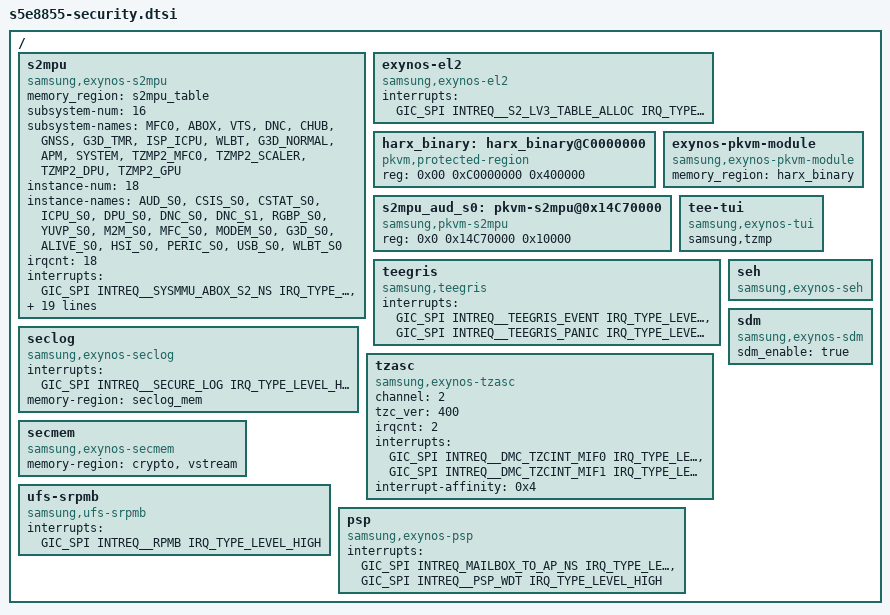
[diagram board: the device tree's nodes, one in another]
/*
 * SAMSUNG S5E8855 SoC security device tree source
 *
 * Copyright (c) 2024 Samsung Electronics Co., Ltd.
 *              http://www.samsung.com
 *
 * SAMSUNG S5E8855 SoC security device nodes are listed in this file.
 * EXYNOS based board files can include this file and provide
 * values for board specfic bindings.
 *
 * This program is free software; you can redistribute it and/or modify
 * it under the terms of the GNU General Public License version 2 as
 * published by the Free Software Foundation.
 */
#include <dt-bindings/interrupt-controller/s5e8855.h>
/ {
	s2mpu {
		compatible = "samsung,exynos-s2mpu";
		memory_region = <&s2mpu_table>;
		subsystem-num = <16>;
		subsystem-names = "MFC0",
				  "ABOX",
				  "VTS",
				  "DNC",
				  "CHUB",
				  "GNSS",
				  "G3D_TMR",
				  "ISP_ICPU",
				  "WLBT",
				  "G3D_NORMAL",
				  "APM",
				  "SYSTEM",
				  "TZMP2_MFC0",
				  "TZMP2_SCALER",
				  "TZMP2_DPU",
				  "TZMP2_GPU";
		instance-num = <18>;
		instance-names = "AUD_S0",
				 "CSIS_S0",
				 "CSTAT_S0",
				 "ICPU_S0",
				 "DPU_S0",
				 "DNC_S0",
				 "DNC_S1",
				 "RGBP_S0",
				 "YUVP_S0",
				 "M2M_S0",
				 "MFC_S0",
				 "MODEM_S0",
				 "G3D_S0",
				 "ALIVE_S0",
				 "HSI_S0",
				 "PERIC_S0",
				 "USB_S0",
				 "WLBT_S0";
		irqcnt = <18>;
		interrupts = <GIC_SPI INTREQ__SYSMMU_ABOX_S2_NS IRQ_TYPE_LEVEL_HIGH>,
			     <GIC_SPI INTREQ__SYSMMU_S0_CSIS_S2_NS IRQ_TYPE_LEVEL_HIGH>,
			     <GIC_SPI INTREQ__SYSMMU_S0_CSTAT_S2_NS IRQ_TYPE_LEVEL_HIGH>,
			     <GIC_SPI INTREQ__SYSMMU_S0_ICPU_S2_NS IRQ_TYPE_LEVEL_HIGH>,
			     <GIC_SPI INTREQ__SYSMMU_DPU_S0_STAGE2_NONSEC IRQ_TYPE_LEVEL_HIGH>,
			     <GIC_SPI INTREQ__FROM_DNC_SYSMMU_DNC_S0_O_STAGE2_NONSEC IRQ_TYPE_LEVEL_HIGH>,
			     <GIC_SPI INTREQ__FROM_DNC_SYSMMU_DNC_S1_O_STAGE2_NONSEC IRQ_TYPE_LEVEL_HIGH>,
			     <GIC_SPI INTREQ__SYSMMU_S0_RGBP_S2_NS IRQ_TYPE_LEVEL_HIGH>,
			     <GIC_SPI INTREQ__SYSMMU_S0_YUVP_S2_NS IRQ_TYPE_LEVEL_HIGH>,
			     <GIC_SPI INTREQ__SYSMMU_S0_M2M_STAGE2_NONSEC IRQ_TYPE_LEVEL_HIGH>,
			     <GIC_SPI INTREQ__SYSMMU_MFC_S0_interrupt_s2_ns IRQ_TYPE_LEVEL_HIGH>,
			     <GIC_SPI INTREQ_SYSMMU_MODEM_S2_NS IRQ_TYPE_LEVEL_HIGH>,
			     <GIC_SPI INTREQ_S2MPU_G3D_S2_NS IRQ_TYPE_LEVEL_HIGH>,
			     <GIC_SPI O_INTERRUPT_STAGE2_NONSEC_ALIVE IRQ_TYPE_LEVEL_HIGH>,
			     <GIC_SPI INTREQ__S2MPU_HSI_S0_S2_NS IRQ_TYPE_LEVEL_HIGH>,
			     <GIC_SPI INTREQ__S2MPU_S0_PERIC_S2_NS IRQ_TYPE_LEVEL_HIGH>,
			     <GIC_SPI INTREQ__S2MPU_USB_S0_S2_NS IRQ_TYPE_LEVEL_HIGH>,
			     <GIC_SPI WB2AP_O_DBUS_INTERRUPT_STAGE2_NONSEC IRQ_TYPE_LEVEL_HIGH>;
		/* PM QoS for SSS */
//		pm-qos-sss-support;
//		sss-freq-domain = "INT";
//		qos-sss-freq = <400000>;
		/* S2MPU version */
		s2mpu-version = <0x90>;
		/* S2MPU Revision version */
		s2mpu-revision = <0x1>;
	};
	exynos-el2 {
		compatible = "samsung,exynos-el2";
		interrupts = <GIC_SPI INTREQ__S2_LV3_TABLE_ALLOC IRQ_TYPE_LEVEL_HIGH>;
	};

	harx_binary: harx_binary@C0000000 {
		compatible = "pkvm,protected-region";
		reg = <0x00 0xC0000000 0x400000>;
	};

	exynos-pkvm-module {
		compatible = "samsung,exynos-pkvm-module";
		memory_region = <&harx_binary>;
	};

//	drm_plugin: drm_plugin@C2800000 {
//	compatible = "pkvm,protected-region";
//	reg = <0x0 0xC2800000 0x100000>;
//	};

	s2mpu_aud_s0: pkvm-s2mpu@0x14C70000 {
		compatible = "samsung,pkvm-s2mpu";
		reg = <0x0 0x14C70000 0x10000>;
	};
	/* tbase */
//	tee {
//		compatible = "samsung,exynos-tee";
//		interrupts = <GIC_SPI INTREQ__TBASE IRQ_TYPE_EDGE_RISING>;
//	};

	tee-tui {
		compatible = "samsung,exynos-tui";
		samsung,tzmp;
	};
//
	/* TEEGRIS */
	teegris {
		compatible = "samsung,teegris";
		interrupts =  <GIC_SPI INTREQ__TEEGRIS_EVENT IRQ_TYPE_LEVEL_HIGH>,
			<GIC_SPI INTREQ__TEEGRIS_PANIC IRQ_TYPE_LEVEL_HIGH>;
	};
	
	/* Secure Log */
	seclog {
		compatible = "samsung,exynos-seclog";
		interrupts = <GIC_SPI INTREQ__SECURE_LOG IRQ_TYPE_LEVEL_HIGH>;
		memory-region = <&seclog_mem>;
	};

	tzasc {
		compatible = "samsung,exynos-tzasc";
		channel = <2>;
		tzc_ver = <400>;
		irqcnt = <2>;
		interrupts = <GIC_SPI INTREQ__DMC_TZCINT_MIF0 IRQ_TYPE_LEVEL_HIGH>,
			   <GIC_SPI INTREQ__DMC_TZCINT_MIF1 IRQ_TYPE_LEVEL_HIGH>;
		/* give affinity to core #2 for TZASC interrupt */
		interrupt-affinity = <0x4>;
	};
//
	seh {
		compatible = "samsung,exynos-seh";
	};

//	ppmpu {
//		compatible = "samsung,exynos-ppmpu";
//		channel = <4>;
//		tzc_ver = <400>;
//		irqcnt = <4>;
//		interrupts = <GIC_SPI INTREQ__DMC_PPMPINT_MIF0 IRQ_TYPE_LEVEL_HIGH>,
//			   <GIC_SPI INTREQ__DMC_PPMPINT_MIF1 IRQ_TYPE_LEVEL_HIGH>,
//			   <GIC_SPI INTREQ__DMC_PPMPINT_MIF2 IRQ_TYPE_LEVEL_HIGH>,
//			   <GIC_SPI INTREQ__DMC_PPMPINT_MIF3 IRQ_TYPE_LEVEL_HIGH>;
//	};
//
//	hdcp {
//		compatible = "samsung,exynos-hdcp";
//		interrupts = <GIC_SPI INTREQ__HDCP IRQ_TYPE_LEVEL_HIGH>;
//	};

	secmem {
		compatible = "samsung,exynos-secmem";
		memory-region = <&crypto>, <&vstream>;
	};

	/* Secure RPMB */
	ufs-srpmb {
		compatible = "samsung,ufs-srpmb";
		interrupts = <GIC_SPI INTREQ__RPMB IRQ_TYPE_LEVEL_HIGH>;
	};

//	fmp {
//		compatible = "samsung,exynos-fmp";
//	};
//
	psp: psp {
		compatible = "samsung,exynos-psp";
		interrupts = <GIC_SPI INTREQ_MAILBOX_TO_AP_NS IRQ_TYPE_LEVEL_HIGH>,
			     <GIC_SPI INTREQ__PSP_WDT IRQ_TYPE_LEVEL_HIGH>;
	};

	/* SecurityDumpManager */
	sdm {
		compatible = "samsung,exynos-sdm";
		sdm_enable = "true";
	};
};
